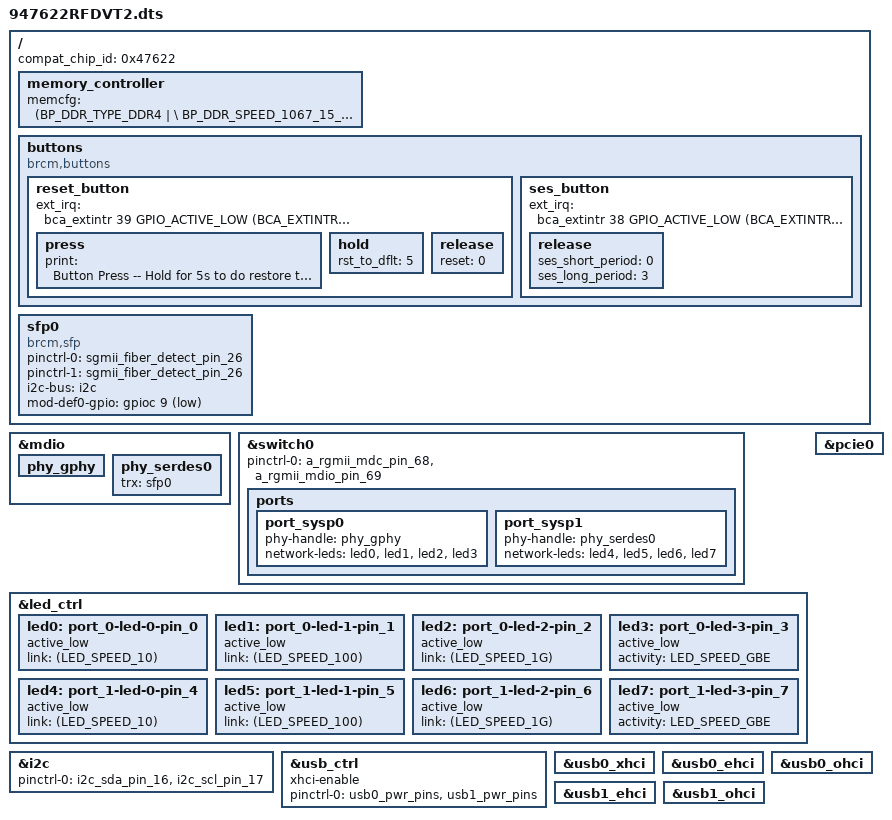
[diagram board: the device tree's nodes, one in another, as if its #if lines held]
#include "47622.dtsi"

/ {
	compat_chip_id = <0x47622>;
    memory_controller {
        memcfg = <(BP_DDR_TYPE_DDR4           | \
                   BP_DDR_SPEED_1067_15_15_15 | \
                   BP_DDR_TOTAL_SIZE_2048MB   | \
                   BP_DDR_DEVICE_WIDTH_8      | \
                   BP_DDR_TOTAL_WIDTH_16BIT   | \
                   BP_DDR_SSC_CONFIG_1)>;
    };

	buttons {
		compatible = "brcm,buttons";
		reset_button {
			ext_irq = <&bca_extintr 39 GPIO_ACTIVE_LOW (BCA_EXTINTR_TYPE_LOW_LEVEL | BCA_EXTINTR_TYPE_SENSE_EDGE)>;
			press {
				print = "Button Press -- Hold for 5s to do restore to default";
			};
			hold {
				rst_to_dflt = <5>;
			};
			release {
				reset = <0>;
			};
		};
		ses_button {
			ext_irq = <&bca_extintr 38 GPIO_ACTIVE_LOW (BCA_EXTINTR_TYPE_LOW_LEVEL | BCA_EXTINTR_TYPE_SENSE_EDGE)>;
			release {
				ses_short_period = <0>;
				ses_long_period = <3>;
			};
		};
	};

	sfp0: sfp0 {
		compatible = "brcm,sfp";
		pinctrl-names = "default", "rx-sd";
		pinctrl-0 = <&sgmii_fiber_detect_pin_26>;
		pinctrl-1 = <&sgmii_fiber_detect_pin_26>;
		i2c-bus = <&i2c>;
		mod-def0-gpio = <&gpioc 9 GPIO_ACTIVE_LOW>;
	};
};


&mdio {
    /* Port PHY mapping:
            port_sysp0 <-->  phy_gphy
            port_sysp1 <-->  phy_serdes0 - sfp0
     */
	phy_gphy {
		status = "okay";
	};

	phy_serdes0 {
		trx = <&sfp0>;
		status = "okay";
	};

};

&switch0 {
	pinctrl-names = "default"; 
	pinctrl-0 = <&a_rgmii_mdc_pin_68 &a_rgmii_mdio_pin_69>; 
	ports {
		/* fixed port configuration */
		port_sysp0 {
			phy-handle = <&phy_gphy>;
			network-leds = <&led0 &led1 &led2 &led3>;
			status = "okay";
		};
		port_sysp1 {
			phy-handle = <&phy_serdes0>;
			network-leds = <&led4 &led5 &led6 &led7>;	
			status = "okay";
		};
	};
};

&led_ctrl {
	led0: port_0-led-0-pin_0 {
		active_low;
		link = <(LED_SPEED_10)>;
		status = "okay";
	};
	led1: port_0-led-1-pin_1 {
		active_low;
		link = <(LED_SPEED_100)>;
		status = "okay";
	};
	led2: port_0-led-2-pin_2 {
		active_low;
		link = <(LED_SPEED_1G)>;
		status = "okay";
	};
	led3: port_0-led-3-pin_3 {
		active_low;
		activity = <LED_SPEED_GBE>;
		status = "okay";
	};
	led4: port_1-led-0-pin_4 {
		active_low;
		link = <(LED_SPEED_10)>;
		status = "okay";
	};
	led5: port_1-led-1-pin_5 {
		active_low;
		link = <(LED_SPEED_100)>;
		status = "okay";
	};
	led6: port_1-led-2-pin_6 {
		active_low;
		link = <(LED_SPEED_1G)>;
		status = "okay";
	};
	led7: port_1-led-3-pin_7 {
		active_low;
		activity = <LED_SPEED_GBE>;
		status = "okay";
	};
};

#if defined(CONFIG_BCM_PCIE_HCD) || defined (CONFIG_BCM_PCIE_HCD_MODULE)
&pcie0 {
	status = "okay";
};
#endif

&i2c {
	pinctrl-names = "default";
	pinctrl-0 = <&i2c_sda_pin_16 &i2c_scl_pin_17>;
	status = "okay";
};

&usb_ctrl {
	status = "okay";
	xhci-enable;
	pinctrl-names = "default";
	pinctrl-0 = <&usb0_pwr_pins &usb1_pwr_pins>;
};

&usb0_xhci {
	status = "okay";
};

&usb0_ehci {
	status = "okay";
};

&usb0_ohci {
	status = "okay";
};

&usb1_ehci {
	status = "okay";
};

&usb1_ohci {
	status = "okay";
};

